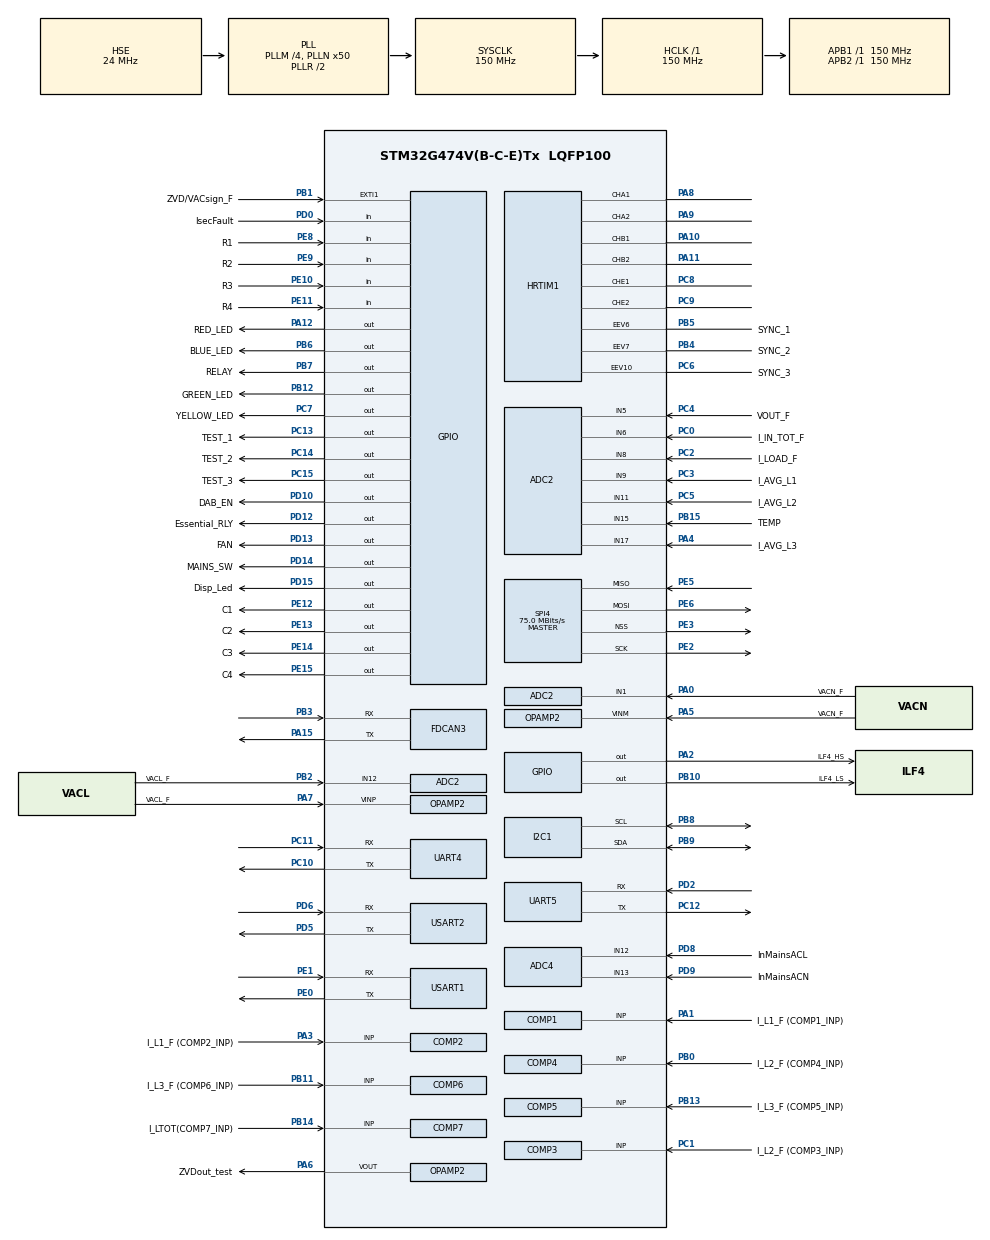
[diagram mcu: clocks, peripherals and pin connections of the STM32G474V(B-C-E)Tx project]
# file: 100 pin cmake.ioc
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ADC2.Channel-0\#ChannelRegularConversion=ADC_CHANNEL_9
ADC2.Channel-1\#ChannelRegularConversion=ADC_CHANNEL_11
ADC2.Channel-2\#ChannelRegularConversion=ADC_CHANNEL_17
ADC2.Channel-3\#ChannelRegularConversion=ADC_CHANNEL_5
ADC2.Channel-4\#ChannelRegularConversion=ADC_CHANNEL_8
ADC2.Channel-5\#ChannelRegularConversion=ADC_CHANNEL_15
ADC2.Channel-6\#ChannelRegularConversion=ADC_CHANNEL_1
ADC2.Channel-7\#ChannelRegularConversion=ADC_CHANNEL_12
ADC2.Channel-8\#ChannelRegularConversion=ADC_CHANNEL_6
ADC2.ClockPrescaler=ADC_CLOCK_ASYNC_DIV32
ADC2.ContinuousConvMode=ENABLE
ADC2.DMAContinuousRequests=ENABLE
ADC2.EOCSelection=ADC_EOC_SEQ_CONV
ADC2.NbrOfConversion=9
ADC2.NbrOfConversionFlag=1
ADC2.OffsetNumber-0\#ChannelRegularConversion=ADC_OFFSET_NONE
ADC2.OffsetNumber-1\#ChannelRegularConversion=ADC_OFFSET_NONE
ADC2.OffsetNumber-2\#ChannelRegularConversion=ADC_OFFSET_NONE
ADC2.OffsetNumber-3\#ChannelRegularConversion=ADC_OFFSET_NONE
ADC2.OffsetNumber-4\#ChannelRegularConversion=ADC_OFFSET_NONE
ADC2.OffsetNumber-5\#ChannelRegularConversion=ADC_OFFSET_NONE
ADC2.OffsetNumber-6\#ChannelRegularConversion=ADC_OFFSET_NONE
ADC2.OffsetNumber-7\#ChannelRegularConversion=ADC_OFFSET_NONE
ADC2.OffsetNumber-8\#ChannelRegularConversion=ADC_OFFSET_NONE
ADC2.Rank-0\#ChannelRegularConversion=1
ADC2.Rank-1\#ChannelRegularConversion=2
ADC2.Rank-2\#ChannelRegularConversion=3
ADC2.Rank-3\#ChannelRegularConversion=4
ADC2.Rank-4\#ChannelRegularConversion=5
ADC2.Rank-5\#ChannelRegularConversion=6
ADC2.Rank-6\#ChannelRegularConversion=7
ADC2.Rank-7\#ChannelRegularConversion=8
ADC2.Rank-8\#ChannelRegularConversion=9
ADC2.SamplingTime-0\#ChannelRegularConversion=ADC_SAMPLETIME_2CYCLES_5
ADC2.SamplingTime-1\#ChannelRegularConversion=ADC_SAMPLETIME_2CYCLES_5
ADC2.SamplingTime-2\#ChannelRegularConversion=ADC_SAMPLETIME_2CYCLES_5
ADC2.SamplingTime-3\#ChannelRegularConversion=ADC_SAMPLETIME_2CYCLES_5
ADC2.SamplingTime-4\#ChannelRegularConversion=ADC_SAMPLETIME_2CYCLES_5
ADC2.SamplingTime-5\#ChannelRegularConversion=ADC_SAMPLETIME_2CYCLES_5
ADC2.SamplingTime-6\#ChannelRegularConversion=ADC_SAMPLETIME_2CYCLES_5
ADC2.SamplingTime-7\#ChannelRegularConversion=ADC_SAMPLETIME_2CYCLES_5
ADC2.SamplingTime-8\#ChannelRegularConversion=ADC_SAMPLETIME_2CYCLES_5
ADC4.Channel-0\#ChannelRegularConversion=ADC_CHANNEL_12
ADC4.Channel-1\#ChannelRegularConversion=ADC_CHANNEL_12
ADC4.ClockPrescaler=ADC_CLOCK_ASYNC_DIV32
ADC4.NbrOfConversion=2
ADC4.NbrOfConversionFlag=1
ADC4.OffsetNumber-0\#ChannelRegularConversion=ADC_OFFSET_NONE
ADC4.OffsetNumber-1\#ChannelRegularConversion=ADC_OFFSET_NONE
ADC4.Rank-0\#ChannelRegularConversion=1
ADC4.Rank-1\#ChannelRegularConversion=2
ADC4.SamplingTime-0\#ChannelRegularConversion=ADC_SAMPLETIME_2CYCLES_5
ADC4.SamplingTime-1\#ChannelRegularConversion=ADC_SAMPLETIME_2CYCLES_5
COMP1.Hysteresis=COMP_HYSTERESIS_NONE
COMP1.TriggerMode=COMP_TRIGGERMODE_IT_FALLING
COMP2.Hysteresis=COMP_HYSTERESIS_NONE
COMP2.TriggerMode=COMP_TRIGGERMODE_IT_RISING
COMP3.Hysteresis=COMP_HYSTERESIS_NONE
COMP3.TriggerMode=COMP_TRIGGERMODE_IT_FALLING
COMP4.Hysteresis=COMP_HYSTERESIS_NONE
COMP4.TriggerMode=COMP_TRIGGERMODE_IT_RISING
COMP5.Hysteresis=COMP_HYSTERESIS_NONE
COMP5.TriggerMode=COMP_TRIGGERMODE_IT_FALLING
COMP6.Hysteresis=COMP_HYSTERESIS_NONE
COMP6.TriggerMode=COMP_TRIGGERMODE_IT_RISING
DAC1.DAC_Channel-DAC_OUT2_Int=DAC_CHANNEL_2
DAC3.DAC_Channel-DAC_OUT2_Int=DAC_CHANNEL_2
DAC4.DAC_Channel-DAC_OUT2_Int=DAC_CHANNEL_2
Dma.ADC2.3.Direction=DMA_PERIPH_TO_MEMORY
Dma.ADC2.3.EventEnable=DISABLE
Dma.ADC2.3.Instance=DMA1_Channel4
Dma.ADC2.3.MemDataAlignment=DMA_MDATAALIGN_HALFWORD
Dma.ADC2.3.MemInc=DMA_MINC_ENABLE
Dma.ADC2.3.Mode=DMA_CIRCULAR
Dma.ADC2.3.PeriphDataAlignment=DMA_PDATAALIGN_HALFWORD
Dma.ADC2.3.PeriphInc=DMA_PINC_DISABLE
Dma.ADC2.3.Polarity=HAL_DMAMUX_REQ_GEN_RISING
Dma.ADC2.3.Priority=DMA_PRIORITY_LOW
Dma.ADC2.3.RequestNumber=1
Dma.ADC2.3.SignalID=NONE
Dma.ADC2.3.SyncEnable=DISABLE
Dma.ADC2.3.SyncPolarity=HAL_DMAMUX_SYNC_NO_EVENT
Dma.ADC2.3.SyncRequestNumber=1
Dma.ADC2.3.SyncSignalID=NONE
Dma.ADC4.7.Direction=DMA_PERIPH_TO_MEMORY
Dma.ADC4.7.EventEnable=DISABLE
Dma.ADC4.7.Instance=DMA1_Channel5
Dma.ADC4.7.MemDataAlignment=DMA_MDATAALIGN_HALFWORD
Dma.ADC4.7.MemInc=DMA_MINC_ENABLE
Dma.ADC4.7.Mode=DMA_NORMAL
Dma.ADC4.7.PeriphDataAlignment=DMA_PDATAALIGN_HALFWORD
Dma.ADC4.7.PeriphInc=DMA_PINC_DISABLE
Dma.ADC4.7.Polarity=HAL_DMAMUX_REQ_GEN_RISING
Dma.ADC4.7.Priority=DMA_PRIORITY_LOW
Dma.ADC4.7.RequestNumber=1
Dma.ADC4.7.SignalID=NONE
Dma.ADC4.7.SyncEnable=DISABLE
Dma.ADC4.7.SyncPolarity=HAL_DMAMUX_SYNC_NO_EVENT
Dma.ADC4.7.SyncRequestNumber=1
Dma.ADC4.7.SyncSignalID=NONE
Dma.HRTIM1_A.0.Direction=DMA_MEMORY_TO_PERIPH
Dma.HRTIM1_A.0.EventEnable=DISABLE
Dma.HRTIM1_A.0.Instance=DMA1_Channel1
Dma.HRTIM1_A.0.MemDataAlignment=DMA_MDATAALIGN_WORD
Dma.HRTIM1_A.0.MemInc=DMA_MINC_DISABLE
Dma.HRTIM1_A.0.Mode=DMA_CIRCULAR
Dma.HRTIM1_A.0.PeriphDataAlignment=DMA_PDATAALIGN_WORD
Dma.HRTIM1_A.0.PeriphInc=DMA_PINC_DISABLE
Dma.HRTIM1_A.0.Polarity=HAL_DMAMUX_REQ_GEN_RISING
Dma.HRTIM1_A.0.Priority=DMA_PRIORITY_LOW
Dma.HRTIM1_A.0.RequestNumber=1
Dma.HRTIM1_A.0.SignalID=NONE
Dma.HRTIM1_A.0.SyncEnable=DISABLE
Dma.HRTIM1_A.0.SyncPolarity=HAL_DMAMUX_SYNC_NO_EVENT
Dma.HRTIM1_A.0.SyncRequestNumber=1
Dma.HRTIM1_A.0.SyncSignalID=NONE
Dma.HRTIM1_B.1.Direction=DMA_MEMORY_TO_PERIPH
Dma.HRTIM1_B.1.EventEnable=DISABLE
Dma.HRTIM1_B.1.Instance=DMA1_Channel2
Dma.HRTIM1_B.1.MemDataAlignment=DMA_MDATAALIGN_WORD
Dma.HRTIM1_B.1.MemInc=DMA_MINC_DISABLE
Dma.HRTIM1_B.1.Mode=DMA_CIRCULAR
Dma.HRTIM1_B.1.PeriphDataAlignment=DMA_PDATAALIGN_WORD
Dma.HRTIM1_B.1.PeriphInc=DMA_PINC_DISABLE
Dma.HRTIM1_B.1.Polarity=HAL_DMAMUX_REQ_GEN_RISING
Dma.HRTIM1_B.1.Priority=DMA_PRIORITY_LOW
Dma.HRTIM1_B.1.RequestNumber=1
Dma.HRTIM1_B.1.SignalID=NONE
Dma.HRTIM1_B.1.SyncEnable=DISABLE
Dma.HRTIM1_B.1.SyncPolarity=HAL_DMAMUX_SYNC_NO_EVENT
Dma.HRTIM1_B.1.SyncRequestNumber=1
Dma.HRTIM1_B.1.SyncSignalID=NONE
Dma.HRTIM1_C.5.Direction=DMA_PERIPH_TO_MEMORY
Dma.HRTIM1_C.5.EventEnable=DISABLE
Dma.HRTIM1_C.5.Instance=DMA1_Channel7
Dma.HRTIM1_C.5.MemDataAlignment=DMA_MDATAALIGN_WORD
Dma.HRTIM1_C.5.MemInc=DMA_MINC_DISABLE
Dma.HRTIM1_C.5.Mode=DMA_CIRCULAR
Dma.HRTIM1_C.5.PeriphDataAlignment=DMA_PDATAALIGN_WORD
Dma.HRTIM1_C.5.PeriphInc=DMA_PINC_DISABLE
Dma.HRTIM1_C.5.Polarity=HAL_DMAMUX_REQ_GEN_RISING
Dma.HRTIM1_C.5.Priority=DMA_PRIORITY_LOW
Dma.HRTIM1_C.5.RequestNumber=1
Dma.HRTIM1_C.5.SignalID=NONE
Dma.HRTIM1_C.5.SyncEnable=DISABLE
Dma.HRTIM1_C.5.SyncPolarity=HAL_DMAMUX_SYNC_NO_EVENT
Dma.HRTIM1_C.5.SyncRequestNumber=1
Dma.HRTIM1_C.5.SyncSignalID=NONE
Dma.HRTIM1_D.4.Direction=DMA_PERIPH_TO_MEMORY
Dma.HRTIM1_D.4.EventEnable=DISABLE
Dma.HRTIM1_D.4.Instance=DMA1_Channel6
Dma.HRTIM1_D.4.MemDataAlignment=DMA_MDATAALIGN_WORD
Dma.HRTIM1_D.4.MemInc=DMA_MINC_DISABLE
Dma.HRTIM1_D.4.Mode=DMA_CIRCULAR
Dma.HRTIM1_D.4.PeriphDataAlignment=DMA_PDATAALIGN_WORD
Dma.HRTIM1_D.4.PeriphInc=DMA_PINC_DISABLE
Dma.HRTIM1_D.4.Polarity=HAL_DMAMUX_REQ_GEN_RISING
Dma.HRTIM1_D.4.Priority=DMA_PRIORITY_LOW
Dma.HRTIM1_D.4.RequestNumber=1
Dma.HRTIM1_D.4.SignalID=NONE
Dma.HRTIM1_D.4.SyncEnable=DISABLE
Dma.HRTIM1_D.4.SyncPolarity=HAL_DMAMUX_SYNC_NO_EVENT
Dma.HRTIM1_D.4.SyncRequestNumber=1
Dma.HRTIM1_D.4.SyncSignalID=NONE
Dma.HRTIM1_E.2.Direction=DMA_PERIPH_TO_MEMORY
Dma.HRTIM1_E.2.EventEnable=DISABLE
Dma.HRTIM1_E.2.Instance=DMA1_Channel3
Dma.HRTIM1_E.2.MemDataAlignment=DMA_MDATAALIGN_WORD
Dma.HRTIM1_E.2.MemInc=DMA_MINC_DISABLE
Dma.HRTIM1_E.2.Mode=DMA_CIRCULAR
Dma.HRTIM1_E.2.PeriphDataAlignment=DMA_PDATAALIGN_WORD
Dma.HRTIM1_E.2.PeriphInc=DMA_PINC_DISABLE
Dma.HRTIM1_E.2.Polarity=HAL_DMAMUX_REQ_GEN_RISING
Dma.HRTIM1_E.2.Priority=DMA_PRIORITY_LOW
Dma.HRTIM1_E.2.RequestNumber=1
Dma.HRTIM1_E.2.SignalID=NONE
Dma.HRTIM1_E.2.SyncEnable=DISABLE
Dma.HRTIM1_E.2.SyncPolarity=HAL_DMAMUX_SYNC_NO_EVENT
Dma.HRTIM1_E.2.SyncRequestNumber=1
Dma.HRTIM1_E.2.SyncSignalID=NONE
Dma.HRTIM1_F.6.Direction=DMA_MEMORY_TO_PERIPH
Dma.HRTIM1_F.6.EventEnable=DISABLE
Dma.HRTIM1_F.6.Instance=DMA1_Channel8
Dma.HRTIM1_F.6.MemDataAlignment=DMA_MDATAALIGN_WORD
Dma.HRTIM1_F.6.MemInc=DMA_MINC_DISABLE
Dma.HRTIM1_F.6.Mode=DMA_CIRCULAR
Dma.HRTIM1_F.6.PeriphDataAlignment=DMA_PDATAALIGN_WORD
Dma.HRTIM1_F.6.PeriphInc=DMA_PINC_DISABLE
Dma.HRTIM1_F.6.Polarity=HAL_DMAMUX_REQ_GEN_RISING
Dma.HRTIM1_F.6.Priority=DMA_PRIORITY_LOW
Dma.HRTIM1_F.6.RequestNumber=1
Dma.HRTIM1_F.6.SignalID=NONE
Dma.HRTIM1_F.6.SyncEnable=DISABLE
Dma.HRTIM1_F.6.SyncPolarity=HAL_DMAMUX_SYNC_NO_EVENT
Dma.HRTIM1_F.6.SyncRequestNumber=1
Dma.HRTIM1_F.6.SyncSignalID=NONE
Dma.Request0=HRTIM1_A
Dma.Request1=HRTIM1_B
Dma.Request2=HRTIM1_E
Dma.Request3=ADC2
Dma.Request4=HRTIM1_D
Dma.Request5=HRTIM1_C
Dma.Request6=HRTIM1_F
Dma.Request7=ADC4
FDCAN3.CalculateBaudRateNominal=3125000
FDCAN3.CalculateTimeBitNominal=320
FDCAN3.CalculateTimeQuantumNominal=106.66666666666667
HRTIM1.CaptureUnit1-No_output_TC=HRTIM_CAPTUREUNIT_1
HRTIM1.CaptureUnit1-No_output_TD=HRTIM_CAPTUREUNIT_1
HRTIM1.CaptureUnit1-No_output_TF=HRTIM_CAPTUREUNIT_1
HRTIM1.CompareUnit1-No_output_TC=HRTIM_COMPAREUNIT_1
HRTIM1.CompareUnit1-No_output_TD=HRTIM_COMPAREUNIT_1
HRTIM1.CompareUnit1-No_output_TF=__NULL
HRTIM1.CompareUnit1-Output_TA1TA2=HRTIM_COMPAREUNIT_1
HRTIM1.CompareUnit1-Output_TB1TB2=HRTIM_COMPAREUNIT_1
HRTIM1.CompareUnit1-Output_TE1TE2=HRTIM_COMPAREUNIT_1
HRTIM1.CompareUnit2-No_output_TD=HRTIM_COMPAREUNIT_2
HRTIM1.CompareUnit2-Output_TA1TA2=HRTIM_COMPAREUNIT_2
HRTIM1.CompareUnit2-Output_TB1TB2=HRTIM_COMPAREUNIT_2
HRTIM1.CompareUnit2-Output_TE1TE2=HRTIM_COMPAREUNIT_2
HRTIM1.CompareUnit3-No_output_TC=HRTIM_COMPAREUNIT_3
HRTIM1.CompareUnit3-No_output_TD=HRTIM_COMPAREUNIT_3
HRTIM1.CompareUnit3-Output_TA1TA2=HRTIM_COMPAREUNIT_3
HRTIM1.CompareUnit3-Output_TB1TB2=HRTIM_COMPAREUNIT_3
HRTIM1.CompareUnit3-Output_TE1TE2=HRTIM_COMPAREUNIT_3
HRTIM1.CompareUnit4-No_output_TC=__NULL
HRTIM1.CompareUnit4-No_output_TD=HRTIM_COMPAREUNIT_4
HRTIM1.CompareUnit4-Output_TA1TA2=HRTIM_COMPAREUNIT_4
HRTIM1.CompareUnit4-Output_TB1TB2=HRTIM_COMPAREUNIT_4
HRTIM1.CompareUnit4-Output_TE1TE2=HRTIM_COMPAREUNIT_4
HRTIM1.CompareValue1-No_output_TC=10
HRTIM1.CompareValue1-No_output_TD=150
HRTIM1.CompareValue1-Output_TE1TE2=10
HRTIM1.CompareValue2-No_output_TD=150
HRTIM1.CompareValue2-Output_TE1TE2=100
HRTIM1.CompareValue3-No_output_TC=10
HRTIM1.CompareValue3-No_output_TD=150
HRTIM1.CompareValue3-Output_TA1TA2=100
HRTIM1.CompareValue3-Output_TB1TB2=100
HRTIM1.CompareValue3-Output_TE1TE2=100
HRTIM1.CompareValue4-No_output_TD=150
HRTIM1.CompareValue4-Output_TA1TA2=4000
HRTIM1.CompareValue4-Output_TB1TB2=4000
HRTIM1.CompareValue4-Output_TE1TE2=65503
HRTIM1.DMARequests1-No_output_TC=HRTIM_TIM_DMA_CPT1
HRTIM1.DMARequests1-No_output_TD=HRTIM_TIM_DMA_CPT1
HRTIM1.DMARequests1-No_output_TF=HRTIM_TIM_DMA_CPT1
HRTIM1.DMASrcAddress-No_output_TC=(uint32_t)&HRTIM1->sTimerxRegs[HRTIM_TIMERINDEX_TIMER_C].CPT1xR;
HRTIM1.DMASrcAddress-No_output_TD=(uint32_t)&HRTIM1->sTimerxRegs[HRTIM_TIMERINDEX_TIMER_D].CPT1xR;
HRTIM1.DMASrcAddress-No_output_TF=(uint32_t)&HRTIM1->sTimerxRegs[HRTIM_TIMERINDEX_TIMER_F].CPT1xR;
HRTIM1.DeadTimeInsertion-Output_TA1TA2=HRTIM_TIMDEADTIMEINSERTION_ENABLED
HRTIM1.DeadTimeInsertion-Output_TB1TB2=HRTIM_TIMDEADTIMEINSERTION_ENABLED
HRTIM1.DeadTimeInsertion-Output_TE1TE2=HRTIM_TIMDEADTIMEINSERTION_ENABLED
HRTIM1.Deadtimeconfig-Output_TA1TA2=HRTIM_TIMERINDEX_TIMER_A
HRTIM1.Deadtimeconfig-Output_TE1TE2=HRTIM_TIMERINDEX_TIMER_E
HRTIM1.Event1-No_output_TD=HRTIM_EVENT_1
HRTIM1.Event1-Output_TA1TA2=__NULL
HRTIM1.Event2-Output_TB1TB2=HRTIM_EVENT_2
HRTIM1.Event3-Output_TE1TE2=__NULL
HRTIM1.Event4-No_output_TD=HRTIM_EVENT_4
HRTIM1.Event4-Output_TA1TA2=__NULL
HRTIM1.Event4-Output_TB1TB2=HRTIM_EVENT_4
HRTIM1.Event5-Output_TB1TB2=HRTIM_EVENT_5
HRTIM1.Event7-Output_TB1TB2=HRTIM_EVENT_7
HRTIM1.Event8-Output_TB1TB2=HRTIM_EVENT_8
HRTIM1.Event9-Output_TE1TE2=__NULL
HRTIM1.Event_EEV1=HRTIM_EVENT_1
HRTIM1.Event_EEV10=HRTIM_EVENT_10
HRTIM1.Event_EEV2=HRTIM_EVENT_2
HRTIM1.Event_EEV3=HRTIM_EVENT_3
HRTIM1.Event_EEV4=HRTIM_EVENT_4
HRTIM1.Event_EEV5=HRTIM_EVENT_5
HRTIM1.Event_EEV6=HRTIM_EVENT_6
HRTIM1.Event_EEV7=HRTIM_EVENT_7
HRTIM1.Event_EEV8=HRTIM_EVENT_8
HRTIM1.Event_EEV9=HRTIM_EVENT_9
HRTIM1.FallingValue-Output_TA1TA2=30
HRTIM1.FallingValue-Output_TB1TB2=30
HRTIM1.FallingValue-Output_TE1TE2=30
HRTIM1.FaultEnable_Source1-Output_TA1TA2=HRTIM_TIMFAULTENABLE_FAULT1
HRTIM1.FaultEnable_Source1-Output_TB1TB2=HRTIM_TIMFAULTENABLE_FAULT2
HRTIM1.FaultEnable_Source1-Output_TE1TE2=HRTIM_TIMFAULTENABLE_FAULT3
HRTIM1.FaultEnable_Source2-Output_TA1TA2=HRTIM_TIMFAULTENABLE_FAULT4
HRTIM1.FaultEnable_Source2-Output_TB1TB2=HRTIM_TIMFAULTENABLE_FAULT5
HRTIM1.FaultEnable_Source2-Output_TE1TE2=HRTIM_TIMFAULTENABLE_FAULT6
HRTIM1.FaultEnable_Source3-Output_TA1TA2=HRTIM_TIMFAULTENABLE_FAULT2
HRTIM1.FaultEnable_Source3-Output_TB1TB2=HRTIM_TIMFAULTENABLE_FAULT1
HRTIM1.FaultEnable_Source3-Output_TE1TE2=HRTIM_TIMFAULTENABLE_FAULT1
HRTIM1.FaultEnable_Source4-Output_TA1TA2=HRTIM_TIMFAULTENABLE_FAULT3
HRTIM1.FaultEnable_Source4-Output_TB1TB2=HRTIM_TIMFAULTENABLE_FAULT3
HRTIM1.FaultEnable_Source4-Output_TE1TE2=HRTIM_TIMFAULTENABLE_FAULT2
HRTIM1.FaultEnable_Source5-Output_TA1TA2=HRTIM_TIMFAULTENABLE_FAULT5
HRTIM1.FaultEnable_Source5-Output_TB1TB2=HRTIM_TIMFAULTENABLE_FAULT4
HRTIM1.FaultEnable_Source5-Output_TE1TE2=HRTIM_TIMFAULTENABLE_FAULT4
HRTIM1.FaultEnable_Source6-Output_TA1TA2=HRTIM_TIMFAULTENABLE_FAULT6
HRTIM1.FaultEnable_Source6-Output_TB1TB2=HRTIM_TIMFAULTENABLE_FAULT6
HRTIM1.FaultEnable_Source6-Output_TE1TE2=HRTIM_TIMFAULTENABLE_FAULT5
HRTIM1.FaultLevel1-Output_TA1TA2=HRTIM_OUTPUTFAULTLEVEL_INACTIVE
HRTIM1.FaultLevel1-Output_TB1TB2=HRTIM_OUTPUTFAULTLEVEL_INACTIVE
HRTIM1.FaultLevel1-Output_TE1TE2=HRTIM_OUTPUTFAULTLEVEL_INACTIVE
HRTIM1.FaultLevel2-Output_TA1TA2=HRTIM_OUTPUTFAULTLEVEL_INACTIVE
HRTIM1.FaultLevel2-Output_TB1TB2=HRTIM_OUTPUTFAULTLEVEL_INACTIVE
HRTIM1.FaultLevel2-Output_TE1TE2=HRTIM_OUTPUTFAULTLEVEL_INACTIVE
HRTIM1.FaultLock-Output_TA1TA2=HRTIM_TIMFAULTLOCK_READONLY
HRTIM1.FaultLock-Output_TB1TB2=HRTIM_TIMFAULTLOCK_READONLY
HRTIM1.FaultLock-Output_TE1TE2=HRTIM_TIMFAULTLOCK_READONLY
HRTIM1.Fault_Line1=HRTIM_FAULT_1
HRTIM1.Fault_Line2=HRTIM_FAULT_2
HRTIM1.Fault_Line3=HRTIM_FAULT_3
HRTIM1.Fault_Line4=HRTIM_FAULT_4
HRTIM1.Fault_Line5=HRTIM_FAULT_5
HRTIM1.Fault_Line6=HRTIM_FAULT_6
HRTIM1.Filter1-No_output_TD=HRTIM_TIMEEVFLT_BLANKINGCMP1
HRTIM1.Filter2-Output_TB1TB2=HRTIM_TIMEEVFLT_BLANKINGCMP3
HRTIM1.Filter4-No_output_TD=HRTIM_TIMEEVFLT_BLANKINGCMP1
HRTIM1.Filter4-Output_TB1TB2=HRTIM_TIMEEVFLT_BLANKINGCMP3
HRTIM1.Filter5-Output_TB1TB2=HRTIM_TIMEEVFLT_BLANKINGCMP3
HRTIM1.Filter7-Output_TB1TB2=HRTIM_TIMEEVFLT_BLANKINGCMP3
HRTIM1.Filter8-Output_TB1TB2=HRTIM_TIMEEVFLT_BLANKINGCMP3
HRTIM1.InterleavedMode-Output_TA1TA2=HRTIM_INTERLEAVED_MODE_DISABLED
HRTIM1.Latch4-Output_TB1TB2=HRTIM_TIMEVENTLATCH_ENABLED
HRTIM1.ModeTimeBase-No_output_TC=HRTIM_MODE_SINGLESHOT_RETRIGGERABLE
HRTIM1.ModeTimeBase-No_output_TD=HRTIM_MODE_SINGLESHOT_RETRIGGERABLE
HRTIM1.ModeTimeBase-No_output_TF=HRTIM_MODE_SINGLESHOT_RETRIGGERABLE
HRTIM1.NumberDMARequests_TA=1
HRTIM1.NumberDMARequests_TB=1
HRTIM1.NumberDMARequests_TC=1
HRTIM1.NumberDMARequests_TD=1
HRTIM1.NumberDMARequests_TE=1
HRTIM1.NumberDMARequests_TF=1
HRTIM1.NumberFaultEnable-Output_TA1TA2=6
HRTIM1.NumberFaultEnable-Output_TB1TB2=6
HRTIM1.NumberFaultEnable-Output_TE1TE2=6
HRTIM1.NumberInterruptRequests-Output_TB1TB2=0
HRTIM1.NumberResetSource1-Output_TA1TA2=1
HRTIM1.NumberResetSource1-Output_TB1TB2=1
HRTIM1.NumberResetSource1-Output_TE1TE2=1
HRTIM1.NumberResetTrigger-No_output_TC=1
HRTIM1.NumberResetTrigger-No_output_TD=2
HRTIM1.NumberResetTrigger-No_output_TF=1
HRTIM1.NumberResetTrigger-Output_TA1TA2=2
HRTIM1.NumberResetTrigger-Output_TB1TB2=2
HRTIM1.NumberResetTrigger-Output_TE1TE2=2
HRTIM1.NumberSetSource1-Output_TA1TA2=1
HRTIM1.NumberSetSource1-Output_TB1TB2=1
HRTIM1.NumberSetSource1-Output_TE1TE2=1
HRTIM1.NumberTriggerSource_Captureconfig1-No_output_TC=1
HRTIM1.NumberTriggerSource_Captureconfig1-No_output_TD=1
HRTIM1.NumberTriggerSource_Captureconfig1-No_output_TF=1
HRTIM1.Periode_TA=2307
HRTIM1.Periode_TB=2307
HRTIM1.Periode_TC=2307
HRTIM1.Periode_TD=2307
HRTIM1.Periode_TE=2307
HRTIM1.Polarity_EEV4=HRTIM_EVENTPOLARITY_LOW
HRTIM1.Polarity_EEV8=HRTIM_EVENTPOLARITY_LOW
HRTIM1.Polarity_EEV9=HRTIM_EVENTPOLARITY_LOW
HRTIM1.Polarity_FaultLine4=HRTIM_FAULTPOLARITY_LOW
HRTIM1.Polarity_FaultLine5=HRTIM_FAULTPOLARITY_LOW
HRTIM1.Polarity_FaultLine6=HRTIM_FAULTPOLARITY_LOW
HRTIM1.PreloadEnable-Output_TA1TA2=HRTIM_PRELOAD_ENABLED
HRTIM1.PreloadEnable-Output_TB1TB2=HRTIM_PRELOAD_ENABLED
HRTIM1.PreloadEnable-Output_TE1TE2=HRTIM_PRELOAD_ENABLED
HRTIM1.PrescalerDead-Output_TA1TA2=HRTIM_TIMDEADTIME_PRESCALERRATIO_DIV1
HRTIM1.PrescalerDead-Output_TB1TB2=HRTIM_TIMDEADTIME_PRESCALERRATIO_DIV1
HRTIM1.PrescalerDead-Output_TE1TE2=HRTIM_TIMDEADTIME_PRESCALERRATIO_DIV1
HRTIM1.PrescalerRatio_TA=HRTIM_PRESCALERRATIO_DIV1
HRTIM1.PrescalerRatio_TB=HRTIM_PRESCALERRATIO_DIV1
HRTIM1.PrescalerRatio_TC=HRTIM_PRESCALERRATIO_DIV1
HRTIM1.PrescalerRatio_TD=HRTIM_PRESCALERRATIO_DIV1
HRTIM1.PrescalerRatio_TE=HRTIM_PRESCALERRATIO_DIV1
HRTIM1.PrescalerRatio_TF=HRTIM_PRESCALERRATIO_DIV1
HRTIM1.RepetitionCounter-Output_TA1TA2=0
HRTIM1.RepetitionCounter-Output_TE1TE2=0
HRTIM1.RepetitionUpdate-Output_TA1TA2=HRTIM_UPDATEONREPETITION_ENABLED
HRTIM1.RepetitionUpdate-Output_TB1TB2=HRTIM_UPDATEONREPETITION_ENABLED
HRTIM1.RepetitionUpdate-Output_TE1TE2=HRTIM_UPDATEONREPETITION_ENABLED
HRTIM1.ResetOutput1_Source1-Output_TA1TA2=HRTIM_OUTPUTRESET_TIMCMP3
HRTIM1.ResetOutput1_Source1-Output_TB1TB2=HRTIM_OUTPUTRESET_TIMCMP3
HRTIM1.ResetOutput1_Source1-Output_TE1TE2=HRTIM_OUTPUTRESET_TIMCMP3
HRTIM1.ResetTrigger1-No_output_TC=HRTIM_TIMRESETTRIGGER_EEV_6
HRTIM1.ResetTrigger1-No_output_TD=HRTIM_TIMRESETTRIGGER_EEV_6
HRTIM1.ResetTrigger1-No_output_TF=HRTIM_TIMRESETTRIGGER_OTHER4_CMP1
HRTIM1.ResetTrigger1-Output_TA1TA2=HRTIM_TIMRESETTRIGGER_NONE
HRTIM1.ResetTrigger1-Output_TB1TB2=HRTIM_TIMRESETTRIGGER_OTHER1_CMP1
HRTIM1.ResetTrigger1-Output_TE1TE2=HRTIM_TIMRESETTRIGGER_OTHER1_CMP4
HRTIM1.ResetTrigger2-Output_TA1TA2=HRTIM_TIMRESETTRIGGER_NONE
HRTIM1.ResetTrigger2-Output_TB1TB2=HRTIM_TIMRESETTRIGGER_NONE
HRTIM1.ResetTrigger2-Output_TE1TE2=HRTIM_TIMRESETTRIGGER_NONE
HRTIM1.RisingValue-Output_TA1TA2=30
HRTIM1.RisingValue-Output_TB1TB2=30
HRTIM1.RisingValue-Output_TE1TE2=30
HRTIM1.Sensitivity_EEV5=HRTIM_EVENTSENSITIVITY_RISINGEDGE
HRTIM1.SetOutput1_Source1-Output_TA1TA2=HRTIM_OUTPUTSET_TIMPER
HRTIM1.SetOutput1_Source1-Output_TB1TB2=HRTIM_OUTPUTSET_TIMBEV1_TIMACMP1
HRTIM1.SetOutput1_Source1-Output_TE1TE2=HRTIM_OUTPUTSET_TIMEEV1_TIMACMP4
HRTIM1.Source_EEV5=HRTIM_EEV5SRC_COMP7_OUT
HRTIM1.Source_EEV8=HRTIM_EEV8SRC_COMP3_OUT
HRTIM1.Source_FaultLine5=HRTIM_FAULTSOURCE_EEVINPUT
HRTIM1.TriggerCapture1_Source1-No_output_TC=HRTIM_CAPTURETRIGGER_EEV_10
HRTIM1.TriggerCapture1_Source1-No_output_TD=HRTIM_CAPTURETRIGGER_EEV_7
HRTIM1.TriggerCapture1_Source1-No_output_TF=HRTIM_CAPTURETRIGGER_EEV_6
I2C1.Timing=0x30D293D6
Mcu.Family=STM32G4
Mcu.Name=STM32G474V(B-C-E)Tx
Mcu.Package=LQFP100
NVIC.COMP1_2_3_IRQn=true\:0\:0\:false\:false\:true\:false\:true\:true
NVIC.COMP4_5_6_IRQn=true\:0\:0\:false\:false\:true\:false\:true\:true
NVIC.DMA1_Channel1_IRQn=true\:15\:0\:true\:false\:true\:false\:true\:true
NVIC.DMA1_Channel2_IRQn=true\:15\:0\:true\:false\:true\:false\:true\:true
NVIC.DMA1_Channel3_IRQn=true\:15\:0\:true\:false\:true\:false\:true\:true
NVIC.DMA1_Channel4_IRQn=true\:15\:0\:true\:false\:true\:false\:true\:true
NVIC.DMA1_Channel5_IRQn=true\:0\:0\:false\:false\:true\:false\:true\:true
NVIC.DMA1_Channel6_IRQn=true\:15\:0\:true\:false\:true\:false\:true\:true
NVIC.DMA1_Channel7_IRQn=true\:15\:0\:true\:false\:true\:false\:true\:true
NVIC.DMA1_Channel8_IRQn=true\:0\:0\:true\:false\:true\:false\:true\:true
NVIC.EXTI1_IRQn=true\:1\:0\:true\:false\:true\:true\:true\:true
NVIC.PriorityGroup=NVIC_PRIORITYGROUP_4
NVIC.TIM2_IRQn=true\:2\:0\:true\:false\:true\:true\:true\:true
NVIC.TIM3_IRQn=true\:1\:0\:true\:false\:true\:true\:true\:true
NVIC.UART4_IRQn=true\:4\:0\:true\:false\:true\:true\:true\:true
OPAMP2.PowerMode=OPAMP_POWERMODE_HIGHSPEED
PA0.GPIO_Label=VACN_F
PA0.Mode=IN1-Single-Ended
PA0.Signal=ADC2_IN1
PA1.GPIO_Label=I_L1_F (COMP1_INP)
PA1.Signal=SharedAnalog_PA1
PA10.GPIO_Speed_High_Default=GPIO_SPEED_FREQ_LOW
PA10.Mode=Output_TB1TB2
PA10.Signal=HRTIM1_CHB1
PA11.GPIO_Speed_High_Default=GPIO_SPEED_FREQ_LOW
PA11.Mode=Output_TB1TB2
PA11.Signal=HRTIM1_CHB2
PA12.GPIO_Label=RED_LED
PA12.PinState=GPIO_PIN_SET
PA12.Signal=GPIO_Output
PA13.Mode=Serial_Wire
PA13.Signal=SYS_JTMS-SWDIO
PA14.Mode=Serial_Wire
PA14.Signal=SYS_JTCK-SWCLK
PA15.Mode=FDCAN_Activate
PA15.Signal=FDCAN3_TX
PA2.GPIO_Label=ILF4_HS
PA2.Signal=GPIO_Output
PA3.GPIO_Label=I_L1_F (COMP2_INP)
PA3.Mode=INP
PA3.Signal=COMP2_INP
PA4.GPIO_Label=I_AVG_L3
PA4.Mode=IN17-Single-Ended
PA4.Signal=ADC2_IN17
PA5.GPIO_Label=VACN_F
PA5.Mode=Standalone
PA5.Signal=OPAMP2_VINM
PA6.GPIO_Label=ZVDout_test
PA6.Mode=Standalone
PA6.Signal=OPAMP2_VOUT
PA7.GPIO_Label=VACL_F
PA7.Signal=SharedAnalog_PA7
PA8.GPIO_Speed_High_Default=GPIO_SPEED_FREQ_LOW
PA8.Mode=Output_TA1TA2
PA8.Signal=HRTIM1_CHA1
PA9.GPIO_Speed_High_Default=GPIO_SPEED_FREQ_LOW
PA9.Mode=Output_TA1TA2
PA9.Signal=HRTIM1_CHA2
PB0.GPIO_Label=I_L2_F (COMP4_INP)
PB0.Mode=INP
PB0.Signal=COMP4_INP
PB1.GPIO_Label=ZVD/VACsign_F
PB1.GPIO_PuPd=GPIO_PULLDOWN
PB1.Signal=GPXTI1
PB10.GPIO_Label=ILF4_LS
PB10.Signal=GPIO_Output
PB11.GPIO_Label=I_L3_F (COMP6_INP)
PB11.Mode=INP
PB11.Signal=COMP6_INP
PB12.GPIO_Label=GREEN_LED
PB12.PinState=GPIO_PIN_SET
PB12.Signal=GPIO_Output
PB13.GPIO_Label=I_L3_F (COMP5_INP)
PB13.Mode=INP
PB13.Signal=COMP5_INP
PB14.GPIO_Label=I_LTOT(COMP7_INP)
PB14.Mode=INP
PB14.Signal=COMP7_INP
PB15.GPIO_Label=TEMP
PB15.Mode=IN15-Single-Ended
PB15.Signal=ADC2_IN15
PB2.GPIO_Label=VACL_F
PB2.Mode=IN12-Single-Ended
PB2.Signal=ADC2_IN12
PB3.Mode=FDCAN_Activate
PB3.Signal=FDCAN3_RX
PB4.GPIO_Label=SYNC_2
PB4.Mode=External_Evt_enable7
PB4.Signal=HRTIM1_EEV7
PB5.GPIO_Label=SYNC_1
PB5.Mode=External_Evt_enable6
PB5.Signal=HRTIM1_EEV6
PB6.GPIO_Label=BLUE_LED
PB6.PinState=GPIO_PIN_SET
PB6.Signal=GPIO_Output
PB7.GPIO_Label=RELAY
PB7.Signal=GPIO_Output
PB8-BOOT0.Mode=I2C
PB8-BOOT0.Signal=I2C1_SCL
PB9.Mode=I2C
PB9.Signal=I2C1_SDA
PC0.GPIO_Label=I_IN_TOT_F
PC0.Mode=IN6-Single-Ended
PC0.Signal=ADC2_IN6
PC1.GPIO_Label=I_L2_F (COMP3_INP)
PC1.Mode=INP
PC1.Signal=COMP3_INP
PC10.Mode=Asynchronous
PC10.Signal=UART4_TX
PC11.Mode=Asynchronous
PC11.Signal=UART4_RX
PC12.Mode=Asynchronous
PC12.Signal=UART5_TX
PC13.GPIO_Label=TEST_1
PC13.Signal=GPIO_Output
PC14-OSC32_IN.GPIO_Label=TEST_2
PC14-OSC32_IN.Signal=GPIO_Output
PC15-OSC32_OUT.GPIO_Label=TEST_3
PC15-OSC32_OUT.Signal=GPIO_Output
PC2.GPIO_Label=I_LOAD_F
PC2.Mode=IN8-Single-Ended
PC2.Signal=ADC2_IN8
PC3.GPIO_Label=I_AVG_L1
PC3.Mode=IN9-Single-Ended
PC3.Signal=ADC2_IN9
PC4.GPIO_Label=VOUT_F
PC4.Mode=IN5-Single-Ended
PC4.Signal=ADC2_IN5
PC5.GPIO_Label=I_AVG_L2
PC5.Mode=IN11-Single-Ended
PC5.Signal=ADC2_IN11
PC6.GPIO_Label=SYNC_3
PC6.Mode=External_Evt_enable10
PC6.Signal=HRTIM1_EEV10
PC7.GPIO_Label=YELLOW_LED
PC7.PinState=GPIO_PIN_SET
PC7.Signal=GPIO_Output
PC8.GPIO_Speed_High_Default=GPIO_SPEED_FREQ_LOW
PC8.Mode=Output_TE1TE2
PC8.Signal=HRTIM1_CHE1
PC9.GPIO_Speed_High_Default=GPIO_SPEED_FREQ_LOW
PC9.Mode=Output_TE1TE2
PC9.Signal=HRTIM1_CHE2
PD0.GPIO_Label=IsecFault
PD0.Signal=GPIO_Input
PD10.GPIO_Label=DAB_EN
PD10.Signal=GPIO_Output
PD12.GPIO_Label=Essential_RLY
PD12.Signal=GPIO_Output
PD13.GPIO_Label=FAN
PD13.Signal=GPIO_Output
PD14.GPIO_Label=MAINS_SW
PD14.Signal=GPIO_Output
PD15.GPIO_Label=Disp_Led
PD15.Signal=GPIO_Output
PD2.Mode=Asynchronous
PD2.Signal=UART5_RX
PD5.Mode=Asynchronous
PD5.Signal=USART2_TX
PD6.Mode=Asynchronous
PD6.Signal=USART2_RX
PD8.GPIO_Label=InMainsACL
PD8.Mode=IN12-Single-Ended
PD8.Signal=ADC4_IN12
PD9.GPIO_Label=InMainsACN
PD9.Mode=IN13-Single-Ended
PD9.Signal=ADC4_IN13
PE0.Mode=Asynchronous
PE0.Signal=USART1_TX
PE1.Mode=Asynchronous
PE1.Signal=USART1_RX
PE10.GPIO_Label=R3
PE10.Signal=GPIO_Input
PE11.GPIO_Label=R4
PE11.Signal=GPIO_Input
PE12.GPIO_Label=C1
PE12.Signal=GPIO_Output
PE13.GPIO_Label=C2
PE13.Signal=GPIO_Output
PE14.GPIO_Label=C3
PE14.Signal=GPIO_Output
PE15.GPIO_Label=C4
PE15.Signal=GPIO_Output
PE2.Mode=Full_Duplex_Master
PE2.Signal=SPI4_SCK
PE3.Mode=NSS_Signal_Hard_Output
PE3.Signal=SPI4_NSS
PE5.Mode=Full_Duplex_Master
PE5.Signal=SPI4_MISO
PE6.Mode=Full_Duplex_Master
PE6.Signal=SPI4_MOSI
PE8.GPIO_Label=R1
PE8.Signal=GPIO_Input
PE9.GPIO_Label=R2
PE9.Signal=GPIO_Input
PF0-OSC_IN.Mode=HSE-External-Oscillator
PF0-OSC_IN.Signal=RCC_OSC_IN
PF1-OSC_OUT.Mode=HSE-External-Oscillator
PF1-OSC_OUT.Signal=RCC_OSC_OUT
ProjectManager.HeapSize=0x200
ProjectManager.StackSize=0x400
ProjectManager.TargetToolchain=CMake
RCC.ADC12Freq_Value=150000000
RCC.ADC345Freq_Value=150000000
RCC.AHBFreq_Value=150000000
RCC.APB1Freq_Value=150000000
RCC.APB1TimFreq_Value=150000000
RCC.APB2Freq_Value=150000000
RCC.APB2TimFreq_Value=150000000
RCC.CortexFreq_Value=150000000
RCC.EXTERNAL_CLOCK_VALUE=12288000
RCC.HCLKFreq_Value=150000000
RCC.HSE_VALUE=24000000
RCC.HSI48_VALUE=48000000
RCC.HSI_VALUE=16000000
RCC.LSE_VALUE=32768
RCC.PLLM=RCC_PLLM_DIV4
RCC.PLLN=50
RCC.PLLSourceVirtual=RCC_PLLSOURCE_HSE
RCC.SYSCLKFreq_VALUE=150000000
RCC.SYSCLKSource=RCC_SYSCLKSOURCE_PLLCLK
RCC.USBFreq_Value=150000000
RCC.VCOOutputFreq_Value=300000000
SH.SharedAnalog_PA1.0=ADC1_IN2
SH.SharedAnalog_PA1.1=COMP1_INP,INP
SH.SharedAnalog_PA7.0=OPAMP2_VINP,Standalone
SH.SharedAnalog_PA7.1=ADC2_IN4,IN4-Single-Ended
SPI4.CalculateBaudRate=75.0 MBits/s
SPI4.Direction=SPI_DIRECTION_2LINES
SPI4.Mode=SPI_MODE_MASTER
SPI4.VirtualNSS=VM_NSSHARD
SPI4.VirtualType=VM_MASTER
TIM2.PeriodNoDither=10000
TIM2.Prescaler=14
TIM3.PeriodNoDither=1000
TIM3.Prescaler=14
USART1.VirtualMode-Asynchronous=VM_ASYNC
USART2.VirtualMode-Asynchronous=VM_ASYNC
VP_COMP1_VS_DAC1OUT1.Mode=INM_DAC1OUT1
VP_COMP2_VS_DAC1OUT2.Mode=INM_DAC1OUT2
VP_COMP3_VS_DAC3OUT1.Mode=INM_DAC3OUT1
VP_COMP4_VS_DAC3OUT2.Mode=INM_DAC3OUT2
VP_COMP5_VS_DAC4OUT1.Mode=INM_DAC4OUT1
VP_COMP6_VS_DAC4OUT2.Mode=INM_DAC4OUT2
VP_COMP7_VS_DAC2OUT1.Mode=INM_DAC2OUT1
VP_DAC1_VS_DACI1.Mode=DAC_OUT1_Int
VP_DAC1_VS_DACI2.Mode=DAC_OUT2_Int
VP_DAC2_VS_DACI1.Mode=DAC_OUT1_Int
VP_DAC3_VS_DACI1.Mode=DAC_OUT1_Int
VP_DAC3_VS_DACI2.Mode=DAC_OUT2_Int
VP_DAC4_VS_DACI1.Mode=DAC_OUT1_Int
VP_DAC4_VS_DACI2.Mode=DAC_OUT2_Int
VP_HRTIM1_VS_hrtimTimerCNoOutput.Mode=No_output_TC
VP_HRTIM1_VS_hrtimTimerDNoOutput.Mode=No_output_TD
VP_HRTIM1_VS_hrtimTimerFNoOutput.Mode=No_output_TF
VP_SYS_VS_DBSignals.Mode=DisableDeadBatterySignals
VP_TIM2_VS_ClockSourceINT.Mode=Internal
VP_TIM3_VS_ClockSourceINT.Mode=Internal
board=custom

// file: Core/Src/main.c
/* USER CODE BEGIN Header */
/**
  ******************************************************************************
  * @file           : main.c
  * @brief          : Main program body
  ******************************************************************************
  * @attention
  *
  * Copyright (c) 2025 STMicroelectronics.
  * All rights reserved.
  *
  * This software is licensed under terms that can be found in the LICENSE file
  * in the root directory of this software component.
  * If no LICENSE file comes with this software, it is provided AS-IS.
  *
  ******************************************************************************
  */
/* USER CODE END Header */
#include "main.h"
#include "adc.h"
#include "comp.h"
#include "dac.h"
#include "dma.h"
#include "fdcan.h"
#include "hrtim.h"
#include "i2c.h"
#include "opamp.h"
#include "spi.h"
#include "tim.h"
#include "usart.h"
#include "gpio.h"

/* USER CODE BEGIN Includes */
#include "DPC_Application.h"
/* USER CODE END Includes */

void SystemClock_Config(void);

int main(void)
{ // minor change to suck a rebuild

  /* MCU Configuration--------------------------------------------------------*/

  /* Reset of all peripherals, Initializes the Flash interface and the Systick. */
  HAL_Init();

  /* Configure the system clock */
  SystemClock_Config();

  /* Initialize all configured peripherals */
  MX_GPIO_Init();
  MX_DMA_Init();

  MX_COMP1_Init();
  MX_COMP2_Init();
  MX_COMP3_Init();
  MX_COMP4_Init();
  MX_COMP5_Init();
  MX_COMP6_Init();
  MX_COMP7_Init();
  MX_DAC1_Init();
  MX_DAC2_Init();
  MX_DAC3_Init();
  MX_DAC4_Init();
  MX_FDCAN3_Init();
  MX_HRTIM1_Init();
  MX_OPAMP2_Init();
  MX_TIM2_Init();
  MX_TIM3_Init();
  MX_UART4_Init();
  MX_UART5_Init();
  MX_I2C1_Init();
  MX_SPI4_Init();
  MX_USART1_UART_Init();
  MX_USART2_UART_Init();
  MX_ADC2_Init();
  MX_ADC4_Init();
  /* USER CODE BEGIN 2 */
  DPC_APPLICATION_Init();
  /* USER CODE END 2 */

  /* Infinite loop */
  /* USER CODE BEGIN WHILE */
  while (1)
  {DPC_APPLICATION_Process();

    /* USER CODE END WHILE */

  }
}

void SystemClock_Config(void)
{
  RCC_OscInitTypeDef RCC_OscInitStruct = {0};
  RCC_ClkInitTypeDef RCC_ClkInitStruct = {0};

  /** Configure the main internal regulator output voltage
  */
  HAL_PWREx_ControlVoltageScaling(PWR_REGULATOR_VOLTAGE_SCALE1);

  /** Initializes the RCC Oscillators according to the specified parameters
  * in the RCC_OscInitTypeDef structure.
  */
  RCC_OscInitStruct.OscillatorType = RCC_OSCILLATORTYPE_HSE;
  RCC_OscInitStruct.HSEState = RCC_HSE_ON;
  RCC_OscInitStruct.PLL.PLLState = RCC_PLL_ON;
  RCC_OscInitStruct.PLL.PLLSource = RCC_PLLSOURCE_HSE;
  RCC_OscInitStruct.PLL.PLLM = RCC_PLLM_DIV4;
  RCC_OscInitStruct.PLL.PLLN = 50;
  RCC_OscInitStruct.PLL.PLLP = RCC_PLLP_DIV2;
  RCC_OscInitStruct.PLL.PLLQ = RCC_PLLQ_DIV2;
  RCC_OscInitStruct.PLL.PLLR = RCC_PLLR_DIV2;
  if (HAL_RCC_OscConfig(&RCC_OscInitStruct) != HAL_OK)
  {
    Error_Handler();
  }

  /** Initializes the CPU, AHB and APB buses clocks
  */
  RCC_ClkInitStruct.ClockType = RCC_CLOCKTYPE_HCLK|RCC_CLOCKTYPE_SYSCLK
                              |RCC_CLOCKTYPE_PCLK1|RCC_CLOCKTYPE_PCLK2;
  RCC_ClkInitStruct.SYSCLKSource = RCC_SYSCLKSOURCE_PLLCLK;
  RCC_ClkInitStruct.AHBCLKDivider = RCC_SYSCLK_DIV1;
  RCC_ClkInitStruct.APB1CLKDivider = RCC_HCLK_DIV1;
  RCC_ClkInitStruct.APB2CLKDivider = RCC_HCLK_DIV1;

  if (HAL_RCC_ClockConfig(&RCC_ClkInitStruct, FLASH_LATENCY_4) != HAL_OK)
  {
    Error_Handler();
  }
}

void Error_Handler(void)
{
  __disable_irq();
  while (1)
  {
  }
}
